VERSION "HIPBNYYYYYYYYYYYYYYYYYYYYYYYYYYYYYYYYYYYYY/4/%%%/4/'%**4YYY///"

NS_ :

BS_:

BU_: PMSM_Emulator Resolver PC
VAL_TABLE_ M_A 1 "自动模式_PMSM Emulator控制旋变" 0 "手动模式_PC直接控制旋变" ;
VAL_TABLE_ mode_switch 1 "position mode" 0 "speed mode" ;
VAL_TABLE_ Debug 11 "Normal" 10 "Debug" ;

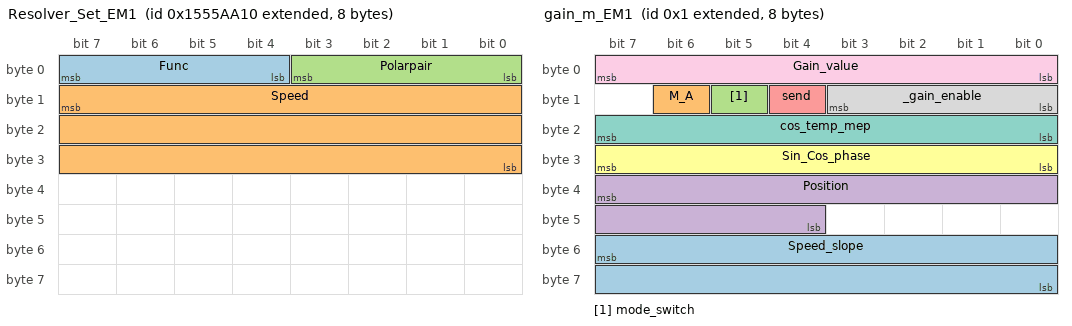
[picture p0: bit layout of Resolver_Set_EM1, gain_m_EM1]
BO_ 2505419280 Resolver_Set_EM1: 8 PC
 SG_ Func : 4|4@1+ (1,0) [0|15] "" Vector__XXX
 SG_ Speed : 15|24@0- (0.619947436,0) [0|0] "r/min" Vector__XXX
 SG_ Polarpair : 0|4@1+ (1,0) [0|15] "" Vector__XXX

BO_ 2147483649 gain_m_EM1: 8 PC
 SG_ Speed_slope : 55|16@0+ (0.909876209,0) [0|0] "(r/min)/s" Vector__XXX
 SG_ M_A : 14|1@1+ (1,0) [0|1] "" Vector__XXX
 SG_ mode_switch : 13|1@1+ (1,0) [0|1] "" Vector__XXX
 SG_ Position : 39|12@0+ (0.36,0) [0|1050] "" Vector__XXX
 SG_ send : 12|1@1+ (1,0) [0|0] "" Vector__XXX
 SG_ Sin_Cos_phase : 31|8@0- (1,0) [0|0] "" Vector__XXX
 SG_ cos_temp_mep : 23|8@0+ (1,0) [0|0] "" Vector__XXX
 SG_ _gain_enable : 8|4@1+ (1,0) [0|14] "" Vector__XXX
 SG_ Gain_value : 0|8@1+ (0.78125,0) [0|0] "" Vector__XXX
